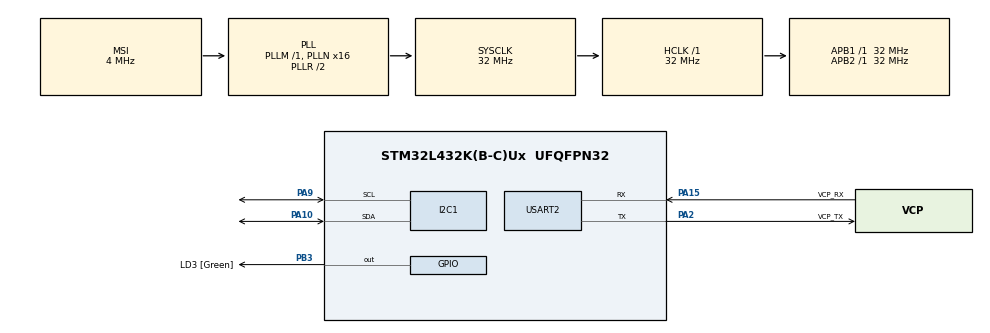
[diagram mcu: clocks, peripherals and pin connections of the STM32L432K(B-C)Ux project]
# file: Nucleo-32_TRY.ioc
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I2C1.Timing=0x00707CBB
Mcu.Family=STM32L4
Mcu.Name=STM32L432K(B-C)Ux
Mcu.Package=UFQFPN32
NVIC.PriorityGroup=NVIC_PRIORITYGROUP_4
PA0.GPIO_Label=MCO [High speed clock in]
PA0.Mode=HSE-External-Clock-Source-for-LittleOrca
PA0.Signal=RCC_CK_IN
PA10.Mode=I2C
PA10.Signal=I2C1_SDA
PA13\ (JTMS-SWDIO).GPIO_Label=SWDIO
PA13\ (JTMS-SWDIO).Mode=Serial_Wire
PA13\ (JTMS-SWDIO).Signal=SYS_JTMS-SWDIO
PA14\ (JTCK-SWCLK).GPIO_Label=SWCLK
PA14\ (JTCK-SWCLK).Mode=Serial_Wire
PA14\ (JTCK-SWCLK).Signal=SYS_JTCK-SWCLK
PA15\ (JTDI).GPIO_Label=VCP_RX
PA15\ (JTDI).Mode=Asynchronous
PA15\ (JTDI).Signal=USART2_RX
PA2.GPIO_Label=VCP_TX
PA2.Mode=Asynchronous
PA2.Signal=USART2_TX
PA9.Mode=I2C
PA9.Signal=I2C1_SCL
PB3\ (JTDO-TRACESWO).GPIO_Label=LD3 [Green]
PB3\ (JTDO-TRACESWO).Signal=GPIO_Output
PC14-OSC32_IN\ (PC14).Mode=LSE-External-Oscillator
PC14-OSC32_IN\ (PC14).Signal=RCC_OSC32_IN
PC15-OSC32_OUT\ (PC15).Mode=LSE-External-Oscillator
PC15-OSC32_OUT\ (PC15).Signal=RCC_OSC32_OUT
ProjectManager.HeapSize=0x200
ProjectManager.StackSize=0x400
ProjectManager.TargetToolchain=MDK-ARM V5
RCC.AHBFreq_Value=32000000
RCC.APB1Freq_Value=32000000
RCC.APB1TimFreq_Value=32000000
RCC.APB2Freq_Value=32000000
RCC.APB2TimFreq_Value=32000000
RCC.CortexFreq_Value=32000000
RCC.HCLKFreq_Value=32000000
RCC.HSE_VALUE=8000000
RCC.HSI16_VALUE=16000000
RCC.HSI48_VALUE=48000000
RCC.HSI_VALUE=16000000
RCC.MSI_VALUE=4000000
RCC.PLLMUL=RCC_PLLMUL_4
RCC.PLLN=16
RCC.SYSCLKFreq_VALUE=32000000
RCC.SYSCLKSource=RCC_SYSCLKSOURCE_PLLCLK
RCC.VCOOutputFreq_Value=64000000
USART2.VirtualMode-Asynchronous=VM_ASYNC
board=NUCLEO-L432KC

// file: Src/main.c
/* USER CODE BEGIN Header */
/**
  ******************************************************************************
  * @file           : main.c
  * @brief          : Main program body
  ******************************************************************************
  * @attention
  *
  * <h2><center>&copy; Copyright (c) 2019 STMicroelectronics.
  * All rights reserved.</center></h2>
  *
  * This software component is licensed by ST under BSD 3-Clause license,
  * the "License"; You may not use this file except in compliance with the
  * License. You may obtain a copy of the License at:
  *                        opensource.org/licenses/BSD-3-Clause
  *
  ******************************************************************************
  */
/* USER CODE END Header */

#include "main.h"
#include "string.h"
#include "MPU6050.h"
#include "stdio.h"

I2C_HandleTypeDef hi2c1;

UART_HandleTypeDef huart2;

void SystemClock_Config(void);
static void MX_GPIO_Init(void);
static void MX_I2C1_Init(void);
static void MX_USART2_UART_Init(void);

/* USER CODE BEGIN 0 */
void Serialprint(char *msg, size_t msg_len)
{

	//uint16_t msg_len = strlen(msg);
	if(!msg_len)	msg_len = strlen(msg);

	HAL_UART_Transmit(&huart2, (uint8_t*)msg , msg_len, 10U);
}
/* USER CODE END 0 */

int main(void)
{

  /* MCU Configuration--------------------------------------------------------*/

  /* Reset of all peripherals, Initializes the Flash interface and the Systick. */
  HAL_Init();

  /* Configure the system clock */
  SystemClock_Config();

  /* Initialize all configured peripherals */
  MX_GPIO_Init();
  MX_I2C1_Init();
  MX_USART2_UART_Init();
  /* USER CODE BEGIN 2 */
  MPU_Init(&hi2c1); // change the I2C as per your requirement
  MPU_Config(CLOCK_INTERNAL,GYRO_FS_250, ACCEL_FS_2, DLPF_BW_5 ,false ); // Set clock Source, Gyro Scale , Accelo Scale, Set Filter, True for enable sleep
  /* USER CODE END 2 */
   int16_t ax, ay,az;
	 char AccelX[10], AccelY[10], AccelZ[10];
	 int L = 0;
	 char _time[4];
	 double axx,ayy,azz;
  /* Infinite loop */

  /* USER CODE BEGIN WHILE */
  while (1)
  {

		uint32_t millis = HAL_GetTick();
    /* USER CODE END WHILE */
		Serialprint("Start Time ", 11);
		float sec = millis/1000.00;
		L = sprintf(_time , "%f",sec);
		Serialprint(_time,0);
		Serialprint("\n\r", 0);
		HAL_GPIO_WritePin(LD3_GPIO_Port, LD3_Pin, GPIO_PIN_RESET);
		HAL_Delay(200);
		Serialprint("AX: ", 0);
		Get_Accel_Raw(&ax,&ay,&az);
		axx = (double)ax/ 16384.0;
		ayy = ((double)ay)/ 16384.0;
		azz = ((double)az)/ 16384.0;
		L = sprintf(AccelX , "%f",axx);
		Serialprint(AccelX, L);
		Serialprint("\n\r", 0);
		L = sprintf(AccelY , "%f",ayy);
		Serialprint("AY: ", 0);
		Serialprint(AccelY, L);
		Serialprint("\n\r", 0);
		L = sprintf(AccelZ , "%f",azz);
		Serialprint("AX: ", 0);
		Serialprint(AccelZ, L);
		Serialprint("\n\r", 0);
		HAL_GPIO_WritePin(LD3_GPIO_Port, LD3_Pin, GPIO_PIN_SET);
		HAL_Delay(200);
		millis = HAL_GetTick();
    /* USER CODE END WHILE */
		float milli = millis/1000.00;
		Serialprint("END Time  ", 9);
		L = sprintf(_time , "%f",milli);
		Serialprint(_time,0);
		Serialprint("\n\r", 0);

//    char buffer[15] = "HELLO WORLD\r\n";
//		HAL_UART_Transmit(&huart2 , (uint8_t*)buffer , sizeof(buffer), 10U);
		//HAL_Delay(500);
  }
}

void SystemClock_Config(void)
{
  RCC_OscInitTypeDef RCC_OscInitStruct = {0};
  RCC_ClkInitTypeDef RCC_ClkInitStruct = {0};
  RCC_PeriphCLKInitTypeDef PeriphClkInit = {0};

  /** Configure LSE Drive Capability
  */
  HAL_PWR_EnableBkUpAccess();
  __HAL_RCC_LSEDRIVE_CONFIG(RCC_LSEDRIVE_LOW);
  /** Initializes the CPU, AHB and APB busses clocks
  */
  RCC_OscInitStruct.OscillatorType = RCC_OSCILLATORTYPE_LSE|RCC_OSCILLATORTYPE_MSI;
  RCC_OscInitStruct.LSEState = RCC_LSE_ON;
  RCC_OscInitStruct.MSIState = RCC_MSI_ON;
  RCC_OscInitStruct.MSICalibrationValue = 0;
  RCC_OscInitStruct.MSIClockRange = RCC_MSIRANGE_6;
  RCC_OscInitStruct.PLL.PLLState = RCC_PLL_ON;
  RCC_OscInitStruct.PLL.PLLSource = RCC_PLLSOURCE_MSI;
  RCC_OscInitStruct.PLL.PLLM = 1;
  RCC_OscInitStruct.PLL.PLLN = 16;
  RCC_OscInitStruct.PLL.PLLP = RCC_PLLP_DIV7;
  RCC_OscInitStruct.PLL.PLLQ = RCC_PLLQ_DIV2;
  RCC_OscInitStruct.PLL.PLLR = RCC_PLLR_DIV2;
  if (HAL_RCC_OscConfig(&RCC_OscInitStruct) != HAL_OK)
  {
    Error_Handler();
  }
  /** Initializes the CPU, AHB and APB busses clocks
  */
  RCC_ClkInitStruct.ClockType = RCC_CLOCKTYPE_HCLK|RCC_CLOCKTYPE_SYSCLK
                              |RCC_CLOCKTYPE_PCLK1|RCC_CLOCKTYPE_PCLK2;
  RCC_ClkInitStruct.SYSCLKSource = RCC_SYSCLKSOURCE_PLLCLK;
  RCC_ClkInitStruct.AHBCLKDivider = RCC_SYSCLK_DIV1;
  RCC_ClkInitStruct.APB1CLKDivider = RCC_HCLK_DIV1;
  RCC_ClkInitStruct.APB2CLKDivider = RCC_HCLK_DIV1;

  if (HAL_RCC_ClockConfig(&RCC_ClkInitStruct, FLASH_LATENCY_1) != HAL_OK)
  {
    Error_Handler();
  }
  PeriphClkInit.PeriphClockSelection = RCC_PERIPHCLK_USART2|RCC_PERIPHCLK_I2C1;
  PeriphClkInit.Usart2ClockSelection = RCC_USART2CLKSOURCE_PCLK1;
  PeriphClkInit.I2c1ClockSelection = RCC_I2C1CLKSOURCE_PCLK1;
  if (HAL_RCCEx_PeriphCLKConfig(&PeriphClkInit) != HAL_OK)
  {
    Error_Handler();
  }
  /** Configure the main internal regulator output voltage
  */
  if (HAL_PWREx_ControlVoltageScaling(PWR_REGULATOR_VOLTAGE_SCALE1) != HAL_OK)
  {
    Error_Handler();
  }
  /** Enable MSI Auto calibration
  */
  HAL_RCCEx_EnableMSIPLLMode();
}

static void MX_I2C1_Init(void)
{

  hi2c1.Instance = I2C1;
  hi2c1.Init.Timing = 0x00707CBB;
  hi2c1.Init.OwnAddress1 = 0;
  hi2c1.Init.AddressingMode = I2C_ADDRESSINGMODE_7BIT;
  hi2c1.Init.DualAddressMode = I2C_DUALADDRESS_DISABLE;
  hi2c1.Init.OwnAddress2 = 0;
  hi2c1.Init.OwnAddress2Masks = I2C_OA2_NOMASK;
  hi2c1.Init.GeneralCallMode = I2C_GENERALCALL_DISABLE;
  hi2c1.Init.NoStretchMode = I2C_NOSTRETCH_DISABLE;
  if (HAL_I2C_Init(&hi2c1) != HAL_OK)
  {
    Error_Handler();
  }
  /** Configure Analogue filter
  */
  if (HAL_I2CEx_ConfigAnalogFilter(&hi2c1, I2C_ANALOGFILTER_ENABLE) != HAL_OK)
  {
    Error_Handler();
  }
  /** Configure Digital filter
  */
  if (HAL_I2CEx_ConfigDigitalFilter(&hi2c1, 0) != HAL_OK)
  {
    Error_Handler();
  }

}

static void MX_USART2_UART_Init(void)
{

  huart2.Instance = USART2;
  huart2.Init.BaudRate = 115200;
  huart2.Init.WordLength = UART_WORDLENGTH_8B;
  huart2.Init.StopBits = UART_STOPBITS_1;
  huart2.Init.Parity = UART_PARITY_NONE;
  huart2.Init.Mode = UART_MODE_TX_RX;
  huart2.Init.HwFlowCtl = UART_HWCONTROL_NONE;
  huart2.Init.OverSampling = UART_OVERSAMPLING_16;
  huart2.Init.OneBitSampling = UART_ONE_BIT_SAMPLE_DISABLE;
  huart2.AdvancedInit.AdvFeatureInit = UART_ADVFEATURE_NO_INIT;
  if (HAL_UART_Init(&huart2) != HAL_OK)
  {
    Error_Handler();
  }

}

static void MX_GPIO_Init(void)
{
  GPIO_InitTypeDef GPIO_InitStruct = {0};

  /* GPIO Ports Clock Enable */
  __HAL_RCC_GPIOC_CLK_ENABLE();
  __HAL_RCC_GPIOA_CLK_ENABLE();
  __HAL_RCC_GPIOB_CLK_ENABLE();

  /*Configure GPIO pin Output Level */
  HAL_GPIO_WritePin(LD3_GPIO_Port, LD3_Pin, GPIO_PIN_RESET);

  /*Configure GPIO pin : LD3_Pin */
  GPIO_InitStruct.Pin = LD3_Pin;
  GPIO_InitStruct.Mode = GPIO_MODE_OUTPUT_PP;
  GPIO_InitStruct.Pull = GPIO_NOPULL;
  GPIO_InitStruct.Speed = GPIO_SPEED_FREQ_LOW;
  HAL_GPIO_Init(LD3_GPIO_Port, &GPIO_InitStruct);

}

void Error_Handler(void)
{
}

/************************ (C) COPYRIGHT STMicroelectronics *****END OF FILE****/
